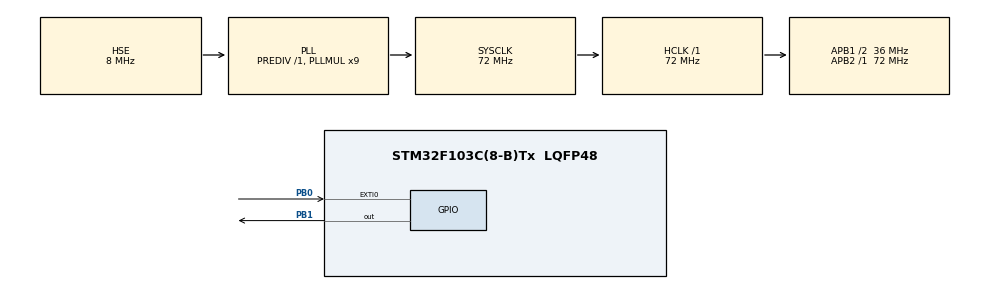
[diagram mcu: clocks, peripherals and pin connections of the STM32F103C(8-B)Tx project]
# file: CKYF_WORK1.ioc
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Mcu.Family=STM32F1
Mcu.Name=STM32F103C(8-B)Tx
Mcu.Package=LQFP48
NVIC.EXTI0_IRQn=true\:2\:0\:true\:false\:true\:true\:true\:true
NVIC.PriorityGroup=NVIC_PRIORITYGROUP_4
NVIC.TIM1_UP_IRQn=true\:3\:0\:true\:false\:true\:true\:true\:true
PA13.Mode=Serial_Wire
PA13.Signal=SYS_JTMS-SWDIO
PA14.Mode=Serial_Wire
PA14.Signal=SYS_JTCK-SWCLK
PB0.GPIO_ModeDefaultEXTI=GPIO_MODE_IT_FALLING
PB0.GPIO_PuPd=GPIO_PULLUP
PB0.Signal=GPXTI0
PB1.PinState=GPIO_PIN_RESET
PB1.Signal=GPIO_Output
PD0-OSC_IN.Mode=HSE-External-Oscillator
PD0-OSC_IN.Signal=RCC_OSC_IN
PD1-OSC_OUT.Mode=HSE-External-Oscillator
PD1-OSC_OUT.Signal=RCC_OSC_OUT
ProjectManager.HeapSize=0x200
ProjectManager.StackSize=0x400
ProjectManager.TargetToolchain=MDK-ARM V5.32
RCC.AHBFreq_Value=72000000
RCC.APB1CLKDivider=RCC_HCLK_DIV2
RCC.APB1Freq_Value=36000000
RCC.APB1TimFreq_Value=72000000
RCC.APB2Freq_Value=72000000
RCC.APB2TimFreq_Value=72000000
RCC.HCLKFreq_Value=72000000
RCC.PLLMUL=RCC_PLL_MUL9
RCC.PLLSourceVirtual=RCC_PLLSOURCE_HSE
RCC.SYSCLKFreq_VALUE=72000000
RCC.SYSCLKSource=RCC_SYSCLKSOURCE_PLLCLK
RCC.USBFreq_Value=72000000
TIM1.AutoReloadPreload=TIM_AUTORELOAD_PRELOAD_ENABLE
TIM1.Period=99
TIM1.Prescaler=7199
VP_TIM1_VS_ClockSourceINT.Mode=Internal
board=custom

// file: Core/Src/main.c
/* USER CODE BEGIN Header */
/**
  ******************************************************************************
  * @file           : main.c
  * @brief          : Main program body
  ******************************************************************************
  * @attention
  *
  * Copyright (c) 2026 STMicroelectronics.
  * All rights reserved.
  *
  * This software is licensed under terms that can be found in the LICENSE file
  * in the root directory of this software component.
  * If no LICENSE file comes with this software, it is provided AS-IS.
  *
  ******************************************************************************
  */
/* USER CODE END Header */
#include "main.h"
#include "tim.h"
#include "gpio.h"

/* USER CODE BEGIN PV */
uint8_t IS_LED_OPEN=0;
uint8_t blinke_cnt;
/* USER CODE END PV */

void SystemClock_Config(void);
/* USER CODE BEGIN PFP */
void MY_PIN_REVERSE(void);//只有pb1的灯,所以写死
void MY_LEDSTATE_REVERSE(void);
/* USER CODE END PFP */

/* USER CODE BEGIN 0 */
void MY_PIN_REVERSE(void)
{
	if(HAL_GPIO_ReadPin(GPIOB,GPIO_PIN_1)==GPIO_PIN_SET)
	{
		HAL_GPIO_WritePin(GPIOB,GPIO_PIN_1,GPIO_PIN_RESET);
	}
	else
		HAL_GPIO_WritePin(GPIOB,GPIO_PIN_1,GPIO_PIN_SET);

}
void MY_LEDSTATE_REVERSE(void)
{
	if(IS_LED_OPEN==0)
	{
		IS_LED_OPEN=1;
	}
	else
	{
		IS_LED_OPEN=0;
	}
}
/* USER CODE END 0 */

int main(void)
{

  /* MCU Configuration--------------------------------------------------------*/

  /* Reset of all peripherals, Initializes the Flash interface and the Systick. */
  HAL_Init();

  /* Configure the system clock */
  SystemClock_Config();

  /* Initialize all configured peripherals */
  MX_GPIO_Init();
  MX_TIM1_Init();
  /* USER CODE BEGIN 2 */
	//前4次闪烁为haldelay500,后续使用tim1中断
	for(uint8_t i=0;i<8;i++)
	{
		MY_PIN_REVERSE();
		HAL_Delay(250);
	}
	//开启tim中断
	HAL_TIM_Base_Start_IT(&htim1);
  /* USER CODE END 2 */

  /* Infinite loop */
  while (1)
  {

  }
}

void SystemClock_Config(void)
{
  RCC_OscInitTypeDef RCC_OscInitStruct = {0};
  RCC_ClkInitTypeDef RCC_ClkInitStruct = {0};

  /** Initializes the RCC Oscillators according to the specified parameters
  * in the RCC_OscInitTypeDef structure.
  */
  RCC_OscInitStruct.OscillatorType = RCC_OSCILLATORTYPE_HSE;
  RCC_OscInitStruct.HSEState = RCC_HSE_ON;
  RCC_OscInitStruct.HSEPredivValue = RCC_HSE_PREDIV_DIV1;
  RCC_OscInitStruct.HSIState = RCC_HSI_ON;
  RCC_OscInitStruct.PLL.PLLState = RCC_PLL_ON;
  RCC_OscInitStruct.PLL.PLLSource = RCC_PLLSOURCE_HSE;
  RCC_OscInitStruct.PLL.PLLMUL = RCC_PLL_MUL9;
  if (HAL_RCC_OscConfig(&RCC_OscInitStruct) != HAL_OK)
  {
    Error_Handler();
  }

  /** Initializes the CPU, AHB and APB buses clocks
  */
  RCC_ClkInitStruct.ClockType = RCC_CLOCKTYPE_HCLK|RCC_CLOCKTYPE_SYSCLK
                              |RCC_CLOCKTYPE_PCLK1|RCC_CLOCKTYPE_PCLK2;
  RCC_ClkInitStruct.SYSCLKSource = RCC_SYSCLKSOURCE_PLLCLK;
  RCC_ClkInitStruct.AHBCLKDivider = RCC_SYSCLK_DIV1;
  RCC_ClkInitStruct.APB1CLKDivider = RCC_HCLK_DIV2;
  RCC_ClkInitStruct.APB2CLKDivider = RCC_HCLK_DIV1;

  if (HAL_RCC_ClockConfig(&RCC_ClkInitStruct, FLASH_LATENCY_2) != HAL_OK)
  {
    Error_Handler();
  }
}

/* USER CODE BEGIN 4 */
void HAL_TIM_PeriodElapsedCallback(TIM_HandleTypeDef *htim)//10ms周期 25分频闪烁
{
	//1.闪烁
	if(IS_LED_OPEN)
	{
		blinke_cnt++;
		if(blinke_cnt>=25)
		{
			MY_PIN_REVERSE();
			blinke_cnt=0;
		}
	}

}
//反正没别的通信，直接haldelay罢（
//systick优先级1，exti2,tim1 3，所以不会卡死
void HAL_GPIO_EXTI_Callback(uint16_t GPIO_Pin)
{
		HAL_Delay(20);
		if(HAL_GPIO_ReadPin(GPIOB,GPIO_PIN_0)==GPIO_PIN_RESET)//低电压说明是按下
		{
				MY_LEDSTATE_REVERSE();
		HAL_GPIO_WritePin(GPIOB,GPIO_PIN_1,GPIO_PIN_RESET);//强制熄灭，统一
			blinke_cnt=0;//统一让开启后等待250ms闪烁
		}

}
/* USER CODE END 4 */

void Error_Handler(void)
{
  __disable_irq();
  while (1)
  {
  }
}
